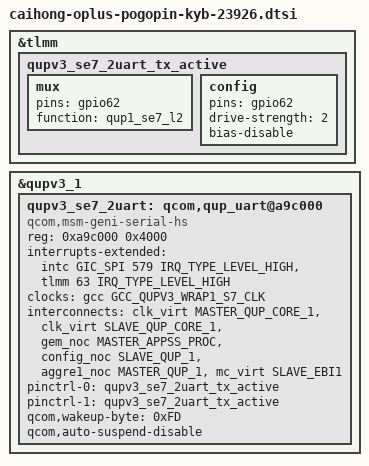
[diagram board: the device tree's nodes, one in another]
#include <dt-bindings/interrupt-controller/irq.h>
#include <dt-bindings/interrupt-controller/arm-gic.h>
#include <dt-bindings/interconnect/qcom,pineapple.h>


&tlmm {
	qupv3_se7_2uart_tx_active: qupv3_se7_2uart_tx_active {
		mux {
			pins = "gpio62";
			function = "qup1_se7_l2";
		};

		config {
			pins = "gpio62";
			drive-strength = <2>;
			bias-disable;
		};
	};
};

&qupv3_1 {
	qupv3_se7_2uart: qcom,qup_uart@a9c000 {
		compatible = "qcom,msm-geni-serial-hs";
		reg = <0xa9c000 0x4000>;
		reg-names = "se_phys";
		interrupts-extended = <&intc GIC_SPI 579 IRQ_TYPE_LEVEL_HIGH>,
			 <&tlmm 63 IRQ_TYPE_LEVEL_HIGH>;
		clock-names = "se-clk";
		clocks = <&gcc GCC_QUPV3_WRAP1_S7_CLK>;
		interconnect-names = "qup-core", "qup-config", "qup-memory";
		interconnects =
		<&clk_virt MASTER_QUP_CORE_1 &clk_virt SLAVE_QUP_CORE_1>,
		<&gem_noc MASTER_APPSS_PROC &config_noc SLAVE_QUP_1>,
		<&aggre1_noc MASTER_QUP_1 &mc_virt  SLAVE_EBI1>;
		pinctrl-names = "default", "sleep";
		pinctrl-0 = <&qupv3_se7_2uart_tx_active>;
		pinctrl-1 = <&qupv3_se7_2uart_tx_active>;
		qcom,wakeup-byte = <0xFD>;
		qcom,auto-suspend-disable;
		status = "ok";
	};
};
